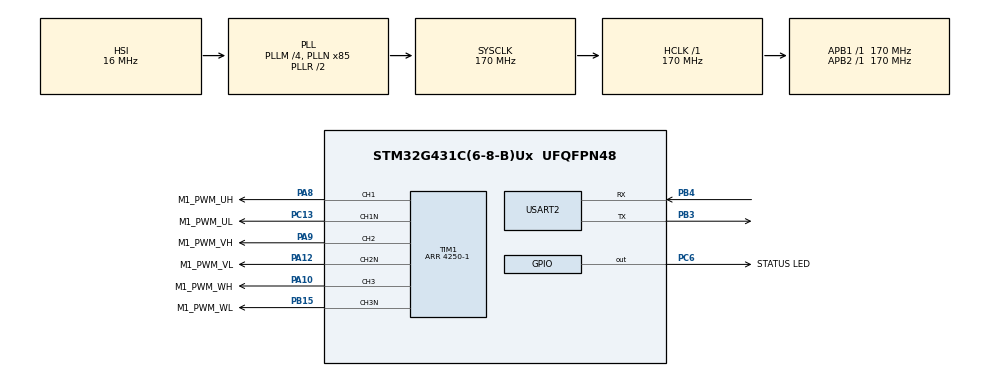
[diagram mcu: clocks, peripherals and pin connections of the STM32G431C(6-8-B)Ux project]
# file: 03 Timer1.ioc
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Dma.Request0=USART2_RX
Dma.Request1=USART2_TX
Dma.USART2_RX.0.Direction=DMA_PERIPH_TO_MEMORY
Dma.USART2_RX.0.EventEnable=DISABLE
Dma.USART2_RX.0.Instance=DMA1_Channel1
Dma.USART2_RX.0.MemDataAlignment=DMA_MDATAALIGN_BYTE
Dma.USART2_RX.0.MemInc=DMA_MINC_ENABLE
Dma.USART2_RX.0.Mode=DMA_CIRCULAR
Dma.USART2_RX.0.PeriphDataAlignment=DMA_PDATAALIGN_BYTE
Dma.USART2_RX.0.PeriphInc=DMA_PINC_DISABLE
Dma.USART2_RX.0.Polarity=HAL_DMAMUX_REQ_GEN_RISING
Dma.USART2_RX.0.Priority=DMA_PRIORITY_LOW
Dma.USART2_RX.0.RequestNumber=1
Dma.USART2_RX.0.SignalID=NONE
Dma.USART2_RX.0.SyncEnable=DISABLE
Dma.USART2_RX.0.SyncPolarity=HAL_DMAMUX_SYNC_NO_EVENT
Dma.USART2_RX.0.SyncRequestNumber=1
Dma.USART2_RX.0.SyncSignalID=NONE
Dma.USART2_TX.1.Direction=DMA_MEMORY_TO_PERIPH
Dma.USART2_TX.1.EventEnable=DISABLE
Dma.USART2_TX.1.Instance=DMA1_Channel2
Dma.USART2_TX.1.MemDataAlignment=DMA_MDATAALIGN_BYTE
Dma.USART2_TX.1.MemInc=DMA_MINC_ENABLE
Dma.USART2_TX.1.Mode=DMA_NORMAL
Dma.USART2_TX.1.PeriphDataAlignment=DMA_PDATAALIGN_BYTE
Dma.USART2_TX.1.PeriphInc=DMA_PINC_DISABLE
Dma.USART2_TX.1.Polarity=HAL_DMAMUX_REQ_GEN_RISING
Dma.USART2_TX.1.Priority=DMA_PRIORITY_LOW
Dma.USART2_TX.1.RequestNumber=1
Dma.USART2_TX.1.SignalID=NONE
Dma.USART2_TX.1.SyncEnable=DISABLE
Dma.USART2_TX.1.SyncPolarity=HAL_DMAMUX_SYNC_NO_EVENT
Dma.USART2_TX.1.SyncRequestNumber=1
Dma.USART2_TX.1.SyncSignalID=NONE
Mcu.Family=STM32G4
Mcu.Name=STM32G431C(6-8-B)Ux
Mcu.Package=UFQFPN48
NVIC.DMA1_Channel1_IRQn=true\:0\:0\:false\:false\:true\:false\:true\:true
NVIC.DMA1_Channel2_IRQn=true\:0\:0\:false\:false\:true\:false\:true\:true
NVIC.PriorityGroup=NVIC_PRIORITYGROUP_4
NVIC.TIM1_UP_TIM16_IRQn=true\:0\:0\:false\:false\:true\:true\:true\:true
NVIC.USART2_IRQn=true\:0\:0\:false\:false\:true\:true\:true\:true
PA10.GPIO_Label=M1_PWM_WH
PA10.Signal=S_TIM1_CH3
PA12.GPIO_Label=M1_PWM_VL
PA12.Mode=PWM Generation2 CH2 CH2N
PA12.Signal=TIM1_CH2N
PA8.GPIO_Label=M1_PWM_UH
PA8.Signal=S_TIM1_CH1
PA9.GPIO_Label=M1_PWM_VH
PA9.Signal=S_TIM1_CH2
PB15.GPIO_Label=M1_PWM_WL
PB15.Mode=PWM Generation3 CH3 CH3N
PB15.Signal=TIM1_CH3N
PB3.Mode=Asynchronous
PB3.Signal=USART2_TX
PB4.Mode=Asynchronous
PB4.Signal=USART2_RX
PC13.GPIO_Label=M1_PWM_UL
PC13.Mode=PWM Generation1 CH1 CH1N
PC13.Signal=TIM1_CH1N
PC6.GPIO_Label=STATUS LED
PC6.Signal=GPIO_Output
PF0-OSC_IN.Mode=HSE-External-Oscillator
PF0-OSC_IN.Signal=RCC_OSC_IN
PF1-OSC_OUT.Mode=HSE-External-Oscillator
PF1-OSC_OUT.Signal=RCC_OSC_OUT
ProjectManager.HeapSize=0x200
ProjectManager.StackSize=0x400
ProjectManager.TargetToolchain=STM32CubeIDE
RCC.ADC12Freq_Value=170000000
RCC.AHBFreq_Value=170000000
RCC.APB1Freq_Value=170000000
RCC.APB1TimFreq_Value=170000000
RCC.APB2Freq_Value=170000000
RCC.APB2TimFreq_Value=170000000
RCC.CortexFreq_Value=170000000
RCC.EXTERNAL_CLOCK_VALUE=12288000
RCC.HCLKFreq_Value=170000000
RCC.HSE_VALUE=8000000
RCC.HSI48_VALUE=48000000
RCC.HSI_VALUE=16000000
RCC.LSE_VALUE=32768
RCC.PLLM=RCC_PLLM_DIV4
RCC.PLLN=85
RCC.SYSCLKFreq_VALUE=170000000
RCC.SYSCLKSource=RCC_SYSCLKSOURCE_PLLCLK
RCC.USBFreq_Value=170000000
RCC.VCOOutputFreq_Value=340000000
SH.S_TIM1_CH1.0=TIM1_CH1,PWM Generation1 CH1 CH1N
SH.S_TIM1_CH2.0=TIM1_CH2,PWM Generation2 CH2 CH2N
SH.S_TIM1_CH3.0=TIM1_CH3,PWM Generation3 CH3 CH3N
TIM1.Channel-PWM\ Generation1\ CH1\ CH1N=TIM_CHANNEL_1
TIM1.Channel-PWM\ Generation2\ CH2\ CH2N=TIM_CHANNEL_2
TIM1.Channel-PWM\ Generation3\ CH3\ CH3N=TIM_CHANNEL_3
TIM1.CounterMode=TIM_COUNTERMODE_CENTERALIGNED3
TIM1.DeadTime=100
TIM1.PeriodNoDither=4250-1
TIM1.PulseNoDither_1=(4250-1)*3/4
TIM1.PulseNoDither_2=(4250-1)*2/4
TIM1.PulseNoDither_3=(4250-1)*1/4
TIM1.TIM_MasterOutputTrigger=TIM_TRGO_RESET
TIM1.TIM_MasterOutputTrigger2=TIM_TRGO2_RESET
USART2.VirtualMode-Asynchronous=VM_ASYNC
VP_SYS_VS_DBSignals.Mode=DisableDeadBatterySignals
VP_TIM1_VS_ClockSourceINT.Mode=Internal
board=custom

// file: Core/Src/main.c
/* USER CODE BEGIN Header */
/**
  ******************************************************************************
  * @file           : main.c
  * @brief          : Main program body
  ******************************************************************************
  * @attention
  *
  * Copyright (c) 2026 STMicroelectronics.
  * All rights reserved.
  *
  * This software is licensed under terms that can be found in the LICENSE file
  * in the root directory of this software component.
  * If no LICENSE file comes with this software, it is provided AS-IS.
  *
  ******************************************************************************
  */
/* USER CODE END Header */
#include "main.h"

/* USER CODE BEGIN Includes */
#include <stdio.h>

#include "serial.h"

/* USER CODE END Includes */

TIM_HandleTypeDef htim1;

UART_HandleTypeDef huart2;
DMA_HandleTypeDef hdma_usart2_rx;
DMA_HandleTypeDef hdma_usart2_tx;

void SystemClock_Config(void);
static void MX_GPIO_Init(void);
static void MX_DMA_Init(void);
static void MX_USART2_UART_Init(void);
static void MX_TIM1_Init(void);

int main(void)
{

  /* MCU Configuration--------------------------------------------------------*/

  /* Reset of all peripherals, Initializes the Flash interface and the Systick. */
  HAL_Init();

  /* Configure the system clock */
  SystemClock_Config();

  /* Initialize all configured peripherals */
  MX_GPIO_Init();
  MX_DMA_Init();
  MX_USART2_UART_Init();
  MX_TIM1_Init();
  /* USER CODE BEGIN 2 */

  /* START TIMER1 */
  HAL_TIM_PWM_Start(&htim1, TIM_CHANNEL_1);
  HAL_TIMEx_PWMN_Start(&htim1, TIM_CHANNEL_1);
  HAL_TIM_PWM_Start(&htim1, TIM_CHANNEL_2);
  HAL_TIMEx_PWMN_Start(&htim1, TIM_CHANNEL_2);
  HAL_TIM_PWM_Start(&htim1, TIM_CHANNEL_3);
  HAL_TIMEx_PWMN_Start(&htim1, TIM_CHANNEL_3);

  HAL_TIM_Base_Start_IT(&htim1);				// for TIM16
  // Initialize your DMA UART framework
  UART_DMA_Init();
  UART_DMA_Printf("Enter target RPM: ");
  /* USER CODE END 2 */

  /* Infinite loop */
  /* USER CODE BEGIN WHILE */
  while (1)
  {
    // Continuously poll the buffer for user keyboard input
	  UART_ProcessCommands();

    /* USER CODE END WHILE */

  }
}

void SystemClock_Config(void)
{
  RCC_OscInitTypeDef RCC_OscInitStruct = {0};
  RCC_ClkInitTypeDef RCC_ClkInitStruct = {0};

  /** Configure the main internal regulator output voltage
  */
  HAL_PWREx_ControlVoltageScaling(PWR_REGULATOR_VOLTAGE_SCALE1_BOOST);

  /** Initializes the RCC Oscillators according to the specified parameters
  * in the RCC_OscInitTypeDef structure.
  */
  RCC_OscInitStruct.OscillatorType = RCC_OSCILLATORTYPE_HSI;
  RCC_OscInitStruct.HSIState = RCC_HSI_ON;
  RCC_OscInitStruct.HSICalibrationValue = RCC_HSICALIBRATION_DEFAULT;
  RCC_OscInitStruct.PLL.PLLState = RCC_PLL_ON;
  RCC_OscInitStruct.PLL.PLLSource = RCC_PLLSOURCE_HSI;
  RCC_OscInitStruct.PLL.PLLM = RCC_PLLM_DIV4;
  RCC_OscInitStruct.PLL.PLLN = 85;
  RCC_OscInitStruct.PLL.PLLP = RCC_PLLP_DIV2;
  RCC_OscInitStruct.PLL.PLLQ = RCC_PLLQ_DIV2;
  RCC_OscInitStruct.PLL.PLLR = RCC_PLLR_DIV2;
  if (HAL_RCC_OscConfig(&RCC_OscInitStruct) != HAL_OK)
  {
    Error_Handler();
  }

  /** Initializes the CPU, AHB and APB buses clocks
  */
  RCC_ClkInitStruct.ClockType = RCC_CLOCKTYPE_HCLK|RCC_CLOCKTYPE_SYSCLK
                              |RCC_CLOCKTYPE_PCLK1|RCC_CLOCKTYPE_PCLK2;
  RCC_ClkInitStruct.SYSCLKSource = RCC_SYSCLKSOURCE_PLLCLK;
  RCC_ClkInitStruct.AHBCLKDivider = RCC_SYSCLK_DIV1;
  RCC_ClkInitStruct.APB1CLKDivider = RCC_HCLK_DIV1;
  RCC_ClkInitStruct.APB2CLKDivider = RCC_HCLK_DIV1;

  if (HAL_RCC_ClockConfig(&RCC_ClkInitStruct, FLASH_LATENCY_4) != HAL_OK)
  {
    Error_Handler();
  }
}

static void MX_TIM1_Init(void)
{

  TIM_ClockConfigTypeDef sClockSourceConfig = {0};
  TIM_MasterConfigTypeDef sMasterConfig = {0};
  TIM_OC_InitTypeDef sConfigOC = {0};
  TIM_BreakDeadTimeConfigTypeDef sBreakDeadTimeConfig = {0};

  htim1.Instance = TIM1;
  htim1.Init.Prescaler = 0;
  htim1.Init.CounterMode = TIM_COUNTERMODE_CENTERALIGNED3;
  htim1.Init.Period = 4249;
  htim1.Init.ClockDivision = TIM_CLOCKDIVISION_DIV1;
  htim1.Init.RepetitionCounter = 0;
  htim1.Init.AutoReloadPreload = TIM_AUTORELOAD_PRELOAD_DISABLE;
  if (HAL_TIM_Base_Init(&htim1) != HAL_OK)
  {
    Error_Handler();
  }
  sClockSourceConfig.ClockSource = TIM_CLOCKSOURCE_INTERNAL;
  if (HAL_TIM_ConfigClockSource(&htim1, &sClockSourceConfig) != HAL_OK)
  {
    Error_Handler();
  }
  if (HAL_TIM_PWM_Init(&htim1) != HAL_OK)
  {
    Error_Handler();
  }
  sMasterConfig.MasterOutputTrigger = TIM_TRGO_RESET;
  sMasterConfig.MasterOutputTrigger2 = TIM_TRGO2_RESET;
  sMasterConfig.MasterSlaveMode = TIM_MASTERSLAVEMODE_DISABLE;
  if (HAL_TIMEx_MasterConfigSynchronization(&htim1, &sMasterConfig) != HAL_OK)
  {
    Error_Handler();
  }
  sConfigOC.OCMode = TIM_OCMODE_PWM1;
  sConfigOC.Pulse = 3186;
  sConfigOC.OCPolarity = TIM_OCPOLARITY_HIGH;
  sConfigOC.OCNPolarity = TIM_OCNPOLARITY_HIGH;
  sConfigOC.OCFastMode = TIM_OCFAST_DISABLE;
  sConfigOC.OCIdleState = TIM_OCIDLESTATE_RESET;
  sConfigOC.OCNIdleState = TIM_OCNIDLESTATE_RESET;
  if (HAL_TIM_PWM_ConfigChannel(&htim1, &sConfigOC, TIM_CHANNEL_1) != HAL_OK)
  {
    Error_Handler();
  }
  sConfigOC.Pulse = 2124;
  if (HAL_TIM_PWM_ConfigChannel(&htim1, &sConfigOC, TIM_CHANNEL_2) != HAL_OK)
  {
    Error_Handler();
  }
  sConfigOC.Pulse = 1062;
  if (HAL_TIM_PWM_ConfigChannel(&htim1, &sConfigOC, TIM_CHANNEL_3) != HAL_OK)
  {
    Error_Handler();
  }
  sBreakDeadTimeConfig.OffStateRunMode = TIM_OSSR_DISABLE;
  sBreakDeadTimeConfig.OffStateIDLEMode = TIM_OSSI_DISABLE;
  sBreakDeadTimeConfig.LockLevel = TIM_LOCKLEVEL_OFF;
  sBreakDeadTimeConfig.DeadTime = 100;
  sBreakDeadTimeConfig.BreakState = TIM_BREAK_DISABLE;
  sBreakDeadTimeConfig.BreakPolarity = TIM_BREAKPOLARITY_HIGH;
  sBreakDeadTimeConfig.BreakFilter = 0;
  sBreakDeadTimeConfig.BreakAFMode = TIM_BREAK_AFMODE_INPUT;
  sBreakDeadTimeConfig.Break2State = TIM_BREAK2_DISABLE;
  sBreakDeadTimeConfig.Break2Polarity = TIM_BREAK2POLARITY_HIGH;
  sBreakDeadTimeConfig.Break2Filter = 0;
  sBreakDeadTimeConfig.Break2AFMode = TIM_BREAK_AFMODE_INPUT;
  sBreakDeadTimeConfig.AutomaticOutput = TIM_AUTOMATICOUTPUT_DISABLE;
  if (HAL_TIMEx_ConfigBreakDeadTime(&htim1, &sBreakDeadTimeConfig) != HAL_OK)
  {
    Error_Handler();
  }
  HAL_TIM_MspPostInit(&htim1);

}

static void MX_USART2_UART_Init(void)
{

  huart2.Instance = USART2;
  huart2.Init.BaudRate = 115200;
  huart2.Init.WordLength = UART_WORDLENGTH_8B;
  huart2.Init.StopBits = UART_STOPBITS_1;
  huart2.Init.Parity = UART_PARITY_NONE;
  huart2.Init.Mode = UART_MODE_TX_RX;
  huart2.Init.HwFlowCtl = UART_HWCONTROL_NONE;
  huart2.Init.OverSampling = UART_OVERSAMPLING_16;
  huart2.Init.OneBitSampling = UART_ONE_BIT_SAMPLE_DISABLE;
  huart2.Init.ClockPrescaler = UART_PRESCALER_DIV1;
  huart2.AdvancedInit.AdvFeatureInit = UART_ADVFEATURE_NO_INIT;
  if (HAL_UART_Init(&huart2) != HAL_OK)
  {
    Error_Handler();
  }
  if (HAL_UARTEx_SetTxFifoThreshold(&huart2, UART_TXFIFO_THRESHOLD_1_8) != HAL_OK)
  {
    Error_Handler();
  }
  if (HAL_UARTEx_SetRxFifoThreshold(&huart2, UART_RXFIFO_THRESHOLD_1_8) != HAL_OK)
  {
    Error_Handler();
  }
  if (HAL_UARTEx_DisableFifoMode(&huart2) != HAL_OK)
  {
    Error_Handler();
  }

}

static void MX_DMA_Init(void)
{

  /* DMA controller clock enable */
  __HAL_RCC_DMAMUX1_CLK_ENABLE();
  __HAL_RCC_DMA1_CLK_ENABLE();

  /* DMA interrupt init */
  /* DMA1_Channel1_IRQn interrupt configuration */
  HAL_NVIC_SetPriority(DMA1_Channel1_IRQn, 0, 0);
  HAL_NVIC_EnableIRQ(DMA1_Channel1_IRQn);
  /* DMA1_Channel2_IRQn interrupt configuration */
  HAL_NVIC_SetPriority(DMA1_Channel2_IRQn, 0, 0);
  HAL_NVIC_EnableIRQ(DMA1_Channel2_IRQn);

}

static void MX_GPIO_Init(void)
{
  GPIO_InitTypeDef GPIO_InitStruct = {0};

  /* GPIO Ports Clock Enable */
  __HAL_RCC_GPIOC_CLK_ENABLE();
  __HAL_RCC_GPIOF_CLK_ENABLE();
  __HAL_RCC_GPIOB_CLK_ENABLE();
  __HAL_RCC_GPIOA_CLK_ENABLE();

  /*Configure GPIO pin Output Level */
  HAL_GPIO_WritePin(STATUS_LED_GPIO_Port, STATUS_LED_Pin, GPIO_PIN_RESET);

  /*Configure GPIO pin : STATUS_LED_Pin */
  GPIO_InitStruct.Pin = STATUS_LED_Pin;
  GPIO_InitStruct.Mode = GPIO_MODE_OUTPUT_PP;
  GPIO_InitStruct.Pull = GPIO_NOPULL;
  GPIO_InitStruct.Speed = GPIO_SPEED_FREQ_LOW;
  HAL_GPIO_Init(STATUS_LED_GPIO_Port, &GPIO_InitStruct);

}

void Error_Handler(void)
{
  __disable_irq();
  while (1)
  {
  }
}
